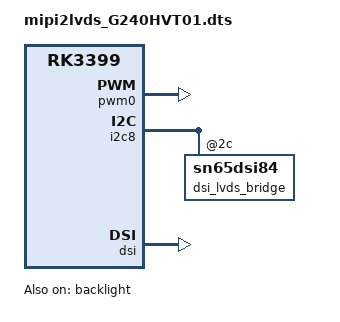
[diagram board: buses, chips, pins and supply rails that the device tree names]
/dts-v1/;
/plugin/;
/ {
	compatible = "rockchip,rk3399";

	fragment@0 {
		target = <&pwm0>;
		__overlay__ {
			status = "okay";
		};
	};
	fragment@1 {
		target = <&backlight>;
		__overlay__ {
			status = "okay";
                        minimal-brightness-level = <26>;
		};
	};
	fragment@2 {
		target = <&i2c8>;
		__overlay__ {
			status = "okay";
			dsi_lvds_bridge: sn65dsi84@2c {
				status = "okay";
				lvds-clk-rate = <72000000>;
				lvds-format = <2>;
				lvds-bpp = <24>;
				dsi-lanes = <4>;
				sync_delay = <33>;
                                dual-link;

				t1=<0>;
				t2=<30>;
				t3=<250>;
				t4=<160>;
				t5=<1>;
				t6=<0>;
				t7=<1000>;
			};
		};
	};
	fragment@3 {
		target = <&dsi>;
		__overlay__ {
			status = "okay";
			panel@0 {
				backlight = <&backlight>;

				width-mm = <531>;
				height-mm = <299>;
				bpc=<8>;
				bus-format = <0x100a>;//<MEDIA_BUS_FMT_RGB888_1X24>;
				dsi,flags = <0x3>;
				dsi,format = <0>;//MIPI_DSI_FMT_RGB888:
				dsi,lanes = <4>;

				display-timings {
					native-mode = <&timing84>;

					timing84: timing84  {
						clock-frequency = <144000000>;
						hactive = <1920>;
						vactive = <1080>;
						hfront-porch = <80>;
						hback-porch = <80>;
						hsync-len = <40>;
						vfront-porch = <15>;
						vsync-len = <10>;
						vback-porch = <15>;
						hsync-active = <0>;
						vsync-active = <0>;
						de-active = <1>;
						pixelclk-active = <0>;
					};
				};
			};
		};
	};
       fragment@4 {
		target = <&pinctrl>;
		__overlay__ {
			pinctrl-0 = <&gpio_init2>;
			gpio_init_config {
				gpio_init2: gpio_init2 {
					rockchip,pins =
						<2 19 0 &pcfg_pull_none>;
				};
			};
		};
	};
};
